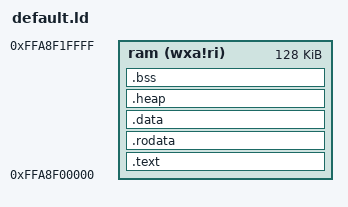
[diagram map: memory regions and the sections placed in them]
OUTPUT_ARCH( "riscv" )

ENTRY( _start )

MEMORY
{
  ram   (wxa!ri) : ORIGIN = 0xFFA8F00000, LENGTH = 128K
}

PHDRS
{
  text PT_LOAD;
  data PT_LOAD;
  bss PT_LOAD;
  heap PT_LOAD;
}

SECTIONS
{
  .text : {
    . = ALIGN(128);
    PROVIDE(_text_start = .);
    *(.text.init) *(.text .text.*)
    PROVIDE(_text_end = .);
  } >ram AT>ram :text

  .rodata : {
    . = ALIGN(128);
    PROVIDE(_rodata_start = .);
    *(.rodata .rodata.*)
    PROVIDE(_rodata_end = .);
  } >ram AT>ram :text

  .data : {
    . = ALIGN(4096);
    PROVIDE(_data_start = .);
    *(.sdata .sdata.*) *(.data .data.*)
    PROVIDE(_data_end = .);
  } >ram AT>ram :data

  .heap : {
    . = ALIGN(128);
    *(heap_riscv);
  } >ram AT>ram :heap

  .bss :{
    . = ALIGN(128);
    PROVIDE(_bss_start = .);
    *(.sbss .sbss.*) *(.bss .bss.*)
    PROVIDE(_bss_end = .);
  } >ram AT>ram :bss

  PROVIDE(_memory_start = ORIGIN(ram));
  PROVIDE(_memory_end = ORIGIN(ram) + LENGTH(ram));
}
